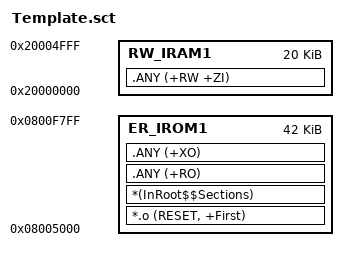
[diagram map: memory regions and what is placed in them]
; *************************************************************
; *** Scatter-Loading Description File generated by uVision ***
; *************************************************************
; 
; 修改说明：APP起始地址从0x08004000调整为0x08005000
; 配合新的Flash分区布局：Boot(16KB) -> Flag(4KB) -> APP(42KB)
; 

LR_IROM1 0x08005000 0x0000A800  {    ; load region size_region (42KB)
  ER_IROM1 0x08005000 0x0000A800  {  ; load address = execution address (42KB)
   *.o (RESET, +First)
   *(InRoot$$Sections)
   .ANY (+RO)
   .ANY (+XO)
  }
  RW_IRAM1 0x20000000 0x00005000  {  ; RW data
   .ANY (+RW +ZI)
  }
}

